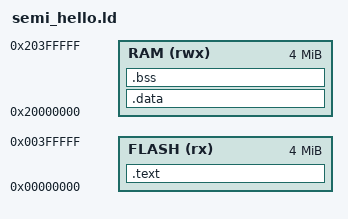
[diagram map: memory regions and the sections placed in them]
/* Linker script for the semi_hello.c test fixture — QEMU mps2-an385 memory map
 * (code region at 0x0, SRAM at 0x20000000). */
OUTPUT_FORMAT("elf32-littlearm")
ENTRY(Reset_Handler)

MEMORY
{
    FLASH (rx)  : ORIGIN = 0x00000000, LENGTH = 4M
    RAM   (rwx) : ORIGIN = 0x20000000, LENGTH = 4M
}

_estack = ORIGIN(RAM) + LENGTH(RAM);

SECTIONS
{
    .text : {
        KEEP(*(.isr_vector))
        *(.text*)
        *(.rodata*)
    } > FLASH
    .data : { *(.data*) } > RAM
    .bss  : { *(.bss*) *(COMMON) } > RAM
}
